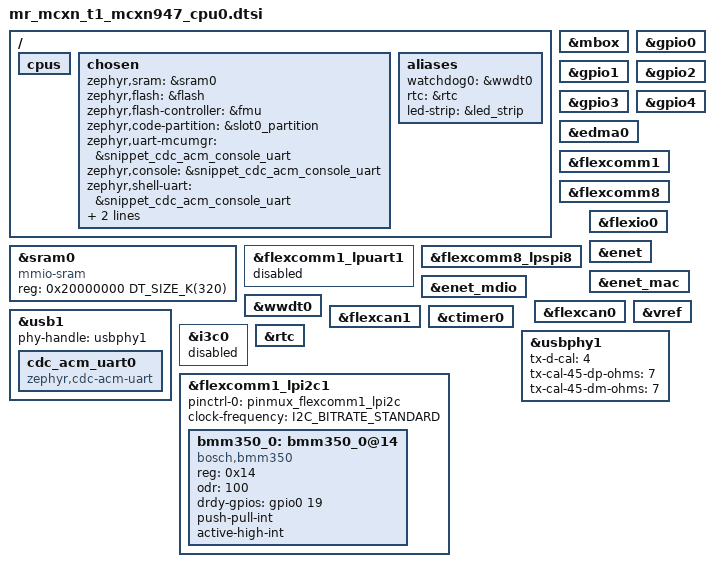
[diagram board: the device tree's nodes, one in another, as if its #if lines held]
/*
 * Copyright 2026 NXP
 * SPDX-License-Identifier: Apache-2.0
 */

/* Common dts file to enable supported features for CPU 0.
 * This file is included by both the default variant
 * which is run from internal flash and the QSPI variant.
 */
/dts-v1/;

#include <nxp/mcx/nxp_mcxn94x.dtsi>
#include "mr_mcxn_t1.dtsi"

/ {
	cpus {
		/delete-node/ cpu@1;
	};

	chosen {
		zephyr,sram = &sram0;
		zephyr,flash = &flash;
		zephyr,flash-controller = &fmu;
		zephyr,code-partition = &slot0_partition;
		zephyr,uart-mcumgr = &cdc_acm_uart0;
		zephyr,console = &cdc_acm_uart0;
		zephyr,shell-uart = &cdc_acm_uart0;
		zephyr,canbus = &flexcan0;
		zephyr,code-cpu1-partition = &slot1_partition;
	};

	aliases {
		watchdog0 = &wwdt0;
		rtc = &rtc;
		led-strip = &led_strip;
	};
};

/*
 * Default for this board is to allocate SRAM0-5 to cpu0 but the
 * application can have an application specific device tree to
 * allocate the SRAM0-7 differently.
 *
 * For example, SRAM0-6 could be allocated to cpu0 with only SRAM7
 * for cpu1. This would require the value of sram0 to have a DT_SIZE_K
 * of 384. You would have to make updates to cpu1 sram settings as well.
 */
&sram0 {
	compatible = "mmio-sram";
	reg = <0x20000000 DT_SIZE_K(320)>;
};

&mbox {
	status = "okay";
};

&gpio0 {
	status = "okay";
};

&gpio1 {
	status = "okay";
};

&gpio2 {
	status = "okay";
};

&gpio3 {
	status = "okay";
};

&gpio4 {
	status = "okay";
};

&edma0 {
	status = "okay";
};

&flexcomm1 {
	status = "okay";
};

&flexcomm1_lpuart1 {
	status = "okay";
};

&flexcomm8 {
	status = "okay";
};

&flexcomm8_lpspi8 {
	status = "okay";
};

&flexio0 {
	status = "okay";
};

&enet {
	status = "okay";
};

&enet_mac {
	status = "okay";
};

&enet_mdio {
	status = "okay";
};

&wwdt0 {
	status = "okay";
};

&flexcan0 {
	status = "okay";
};

&flexcan1 {
	status = "okay";
};

&ctimer0 {
	status = "okay";
};

&vref {
	status = "okay";
};

zephyr_udc0: &usb1 {
	status = "okay";
	phy-handle = <&usbphy1>;

	cdc_acm_uart0: cdc_acm_uart0 {
		compatible = "zephyr,cdc-acm-uart";
	};
};

&usbphy1 {
	status = "okay";
	tx-d-cal = <4>;
	tx-cal-45-dp-ohms = <7>;
	tx-cal-45-dm-ohms = <7>;
};

&i3c0 {
	status = "okay"; /* Locks-up on startup with busy wait */
};

&bmm350_0 {
	status = "okay"; /* Locks-up on startup with busy wait */
};

&rtc {
	status = "okay";
};

/* Due to the I3C performance issue on BMM350, we're going with
 * I2C native + USB CDC ACM for console.
 */

#if CONFIG_MCXN_T1_I3C_WORKAROUND

&i3c0 {
	status = "disabled";
};

&flexcomm1_lpuart1 {
	status = "disabled";
};

/delete-node/&bmm350_0;
/delete-node/&bmp581_0;

&flexcomm1_lpi2c1 {
	status = "okay";
	pinctrl-0 = <&pinmux_flexcomm1_lpi2c>;
	pinctrl-names = "default";
	clock-frequency = <I2C_BITRATE_STANDARD>;

	bmm350_0: bmm350_0@14  {
		compatible = "bosch,bmm350";
		reg = <0x14>;
		odr = "100";
		drdy-gpios = <&gpio0 19 GPIO_ACTIVE_HIGH>;
		push-pull-int;
		active-high-int;
	};
};

/ {
	chosen {
		zephyr,console = &snippet_cdc_acm_console_uart;
		zephyr,shell-uart = &snippet_cdc_acm_console_uart;
		zephyr,uart-mcumgr = &snippet_cdc_acm_console_uart;
		};
};
#endif
